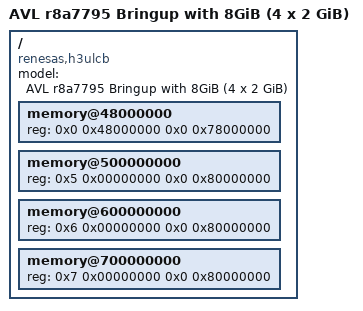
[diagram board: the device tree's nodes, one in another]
// SPDX-License-Identifier: GPL-2.0
/*
 * Copyright (C) 2018 Renesas Electronics Corporaton.
 * Copyright (C) 2019 AVL
 */

#include "r8a7795-avl.dts"

/ {
	model = "AVL r8a7795 Bringup with 8GiB (4 x 2 GiB)";
	compatible = "renesas,h3ulcb", "renesas,r8a7795", "avl, bringup";

	memory@48000000 {
		device_type = "memory";
		/* first 128MB is reserved for secure area. */
		reg = <0x0 0x48000000 0x0 0x78000000>;
	};

	memory@500000000 {
		device_type = "memory";
		reg = <0x5 0x00000000 0x0 0x80000000>;
	};

	memory@600000000 {
		device_type = "memory";
		reg = <0x6 0x00000000 0x0 0x80000000>;
	};

	memory@700000000 {
		device_type = "memory";
		reg = <0x7 0x00000000 0x0 0x80000000>;
	};
};
